VERSION ""

NS_ :

BS_:

BU_: GWM VCU Tester
VAL_TABLE_ New_Value_Table_1 1 "Valid" 0 "Invalid" ;

BO_ 1921 Vcu_Uds_Response: 8 VCU
 SG_ Uds_Resp : 7|64@0+ (1,0) [0|0] ""  Tester

BO_ 1793 Vcu_Uds_Phy_Request: 8 Tester
 SG_ Uds_Phy_Req : 7|64@0+ (1,0) [0|0] ""  VCU

BO_ 1792 Vcu_Uds_Func_Request: 8 Tester
 SG_ Uds_Func_Req : 7|64@0+ (1,0) [0|0] ""  VCU

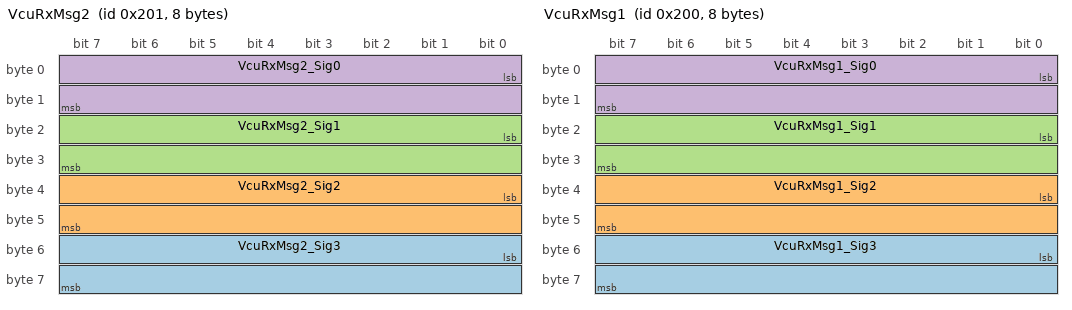
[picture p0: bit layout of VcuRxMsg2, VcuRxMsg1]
BO_ 513 VcuRxMsg2: 8 GWM
 SG_ VcuRxMsg2_Sig3 : 48|16@1- (1,0) [0|0] ""  VCU
 SG_ VcuRxMsg2_Sig2 : 32|16@1- (1,0) [0|0] ""  VCU
 SG_ VcuRxMsg2_Sig1 : 16|16@1- (1,0) [0|0] ""  VCU
 SG_ VcuRxMsg2_Sig0 : 0|16@1- (1,0) [0|0] ""  VCU

BO_ 512 VcuRxMsg1: 8 GWM
 SG_ VcuRxMsg1_Sig3 : 48|16@1- (1,0) [0|0] ""  VCU
 SG_ VcuRxMsg1_Sig2 : 32|16@1- (1,0) [0|0] ""  VCU
 SG_ VcuRxMsg1_Sig1 : 16|16@1- (1,0) [0|0] ""  VCU
 SG_ VcuRxMsg1_Sig0 : 0|16@1- (1,0) [0|0] ""  VCU

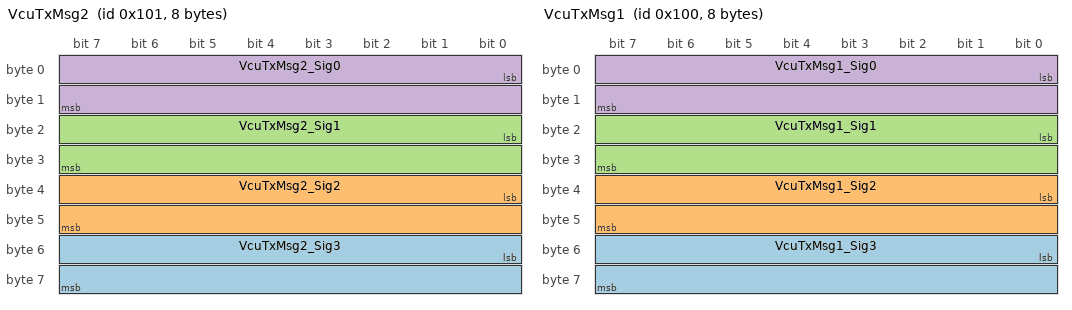
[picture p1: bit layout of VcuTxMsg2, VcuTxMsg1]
BO_ 257 VcuTxMsg2: 8 VCU
 SG_ VcuTxMsg2_Sig3 : 48|16@1- (1,0) [0|0] ""  GWM
 SG_ VcuTxMsg2_Sig2 : 32|16@1- (1,0) [0|0] ""  GWM
 SG_ VcuTxMsg2_Sig1 : 16|16@1- (1,0) [0|0] ""  GWM
 SG_ VcuTxMsg2_Sig0 : 0|16@1- (1,0) [0|0] ""  GWM

BO_ 256 VcuTxMsg1: 8 VCU
 SG_ VcuTxMsg1_Sig3 : 48|16@1- (1,0) [0|0] ""  GWM
 SG_ VcuTxMsg1_Sig2 : 32|16@1- (1,0) [0|0] ""  GWM
 SG_ VcuTxMsg1_Sig1 : 16|16@1- (1,0) [0|0] ""  GWM
 SG_ VcuTxMsg1_Sig0 : 0|16@1- (1,0) [0|0] ""  GWM

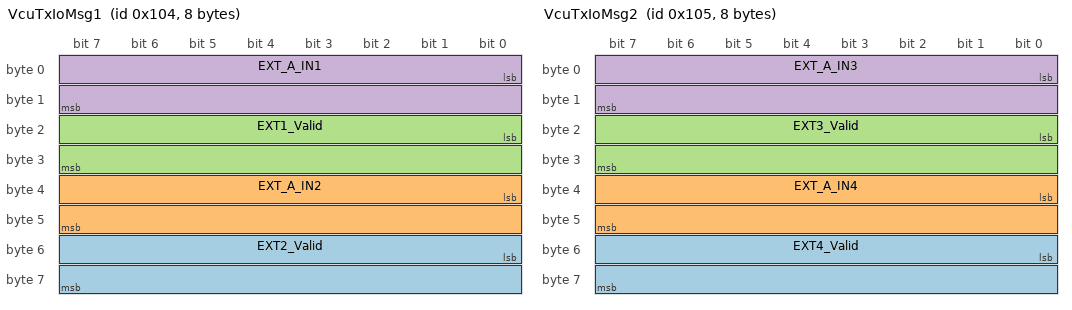
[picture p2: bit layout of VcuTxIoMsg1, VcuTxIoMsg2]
BO_ 260 VcuTxIoMsg1: 8 VCU
 SG_ EXT2_Valid : 48|16@1+ (1,0) [0|1] ""  GWM
 SG_ EXT_A_IN2 : 32|16@1- (1,0) [0|0] "°„C"  GWM
 SG_ EXT1_Valid : 16|16@1+ (1,0) [0|1] ""  GWM
 SG_ EXT_A_IN1 : 0|16@1- (1,0) [-256|255] "°„C"  GWM

BO_ 261 VcuTxIoMsg2: 8 VCU
 SG_ EXT4_Valid : 48|16@1+ (1,0) [0|1] ""  GWM
 SG_ EXT_A_IN4 : 32|16@1- (1,0) [0|0] "°„C"  GWM
 SG_ EXT3_Valid : 16|16@1+ (1,0) [0|1] ""  GWM
 SG_ EXT_A_IN3 : 0|16@1- (1,0) [-256|255] "°„C"  GWM

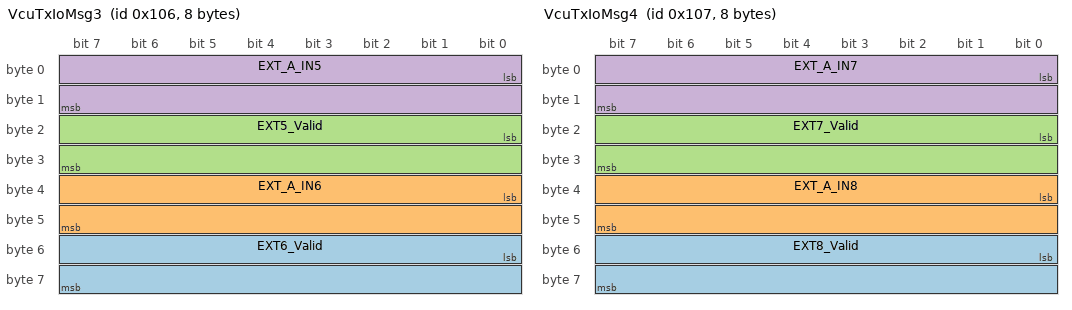
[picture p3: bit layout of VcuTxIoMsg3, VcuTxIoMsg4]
BO_ 262 VcuTxIoMsg3: 8 VCU
 SG_ EXT6_Valid : 48|16@1+ (1,0) [0|1] ""  GWM
 SG_ EXT_A_IN6 : 32|16@1- (1,0) [0|0] "°„C"  GWM
 SG_ EXT5_Valid : 16|16@1+ (1,0) [0|1] ""  GWM
 SG_ EXT_A_IN5 : 0|16@1- (1,0) [-256|255] "°„C"  GWM

BO_ 263 VcuTxIoMsg4: 8 VCU
 SG_ EXT8_Valid : 48|16@1+ (1,0) [0|1] ""  GWM
 SG_ EXT_A_IN8 : 32|16@1- (1,0) [0|0] "°„C"  GWM
 SG_ EXT7_Valid : 16|16@1+ (1,0) [0|1] ""  GWM
 SG_ EXT_A_IN7 : 0|16@1- (1,0) [-256|255] "°„C"  GWM

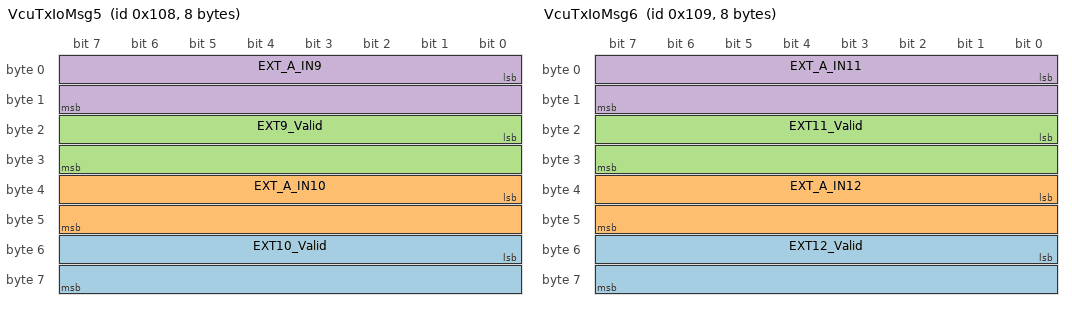
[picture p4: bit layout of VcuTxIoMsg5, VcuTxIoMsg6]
BO_ 264 VcuTxIoMsg5: 8 VCU
 SG_ EXT10_Valid : 48|16@1+ (1,0) [0|1] ""  GWM
 SG_ EXT_A_IN10 : 32|16@1- (1,0) [0|0] "°„C"  GWM
 SG_ EXT9_Valid : 16|16@1+ (1,0) [0|1] ""  GWM
 SG_ EXT_A_IN9 : 0|16@1- (1,0) [-256|255] "°„C"  GWM

BO_ 265 VcuTxIoMsg6: 8 VCU
 SG_ EXT12_Valid : 48|16@1+ (1,0) [0|1] ""  GWM
 SG_ EXT_A_IN12 : 32|16@1- (1,0) [0|0] "°„C"  GWM
 SG_ EXT11_Valid : 16|16@1+ (1,0) [0|1] ""  GWM
 SG_ EXT_A_IN11 : 0|16@1- (1,0) [-256|255] "°„C"  GWM

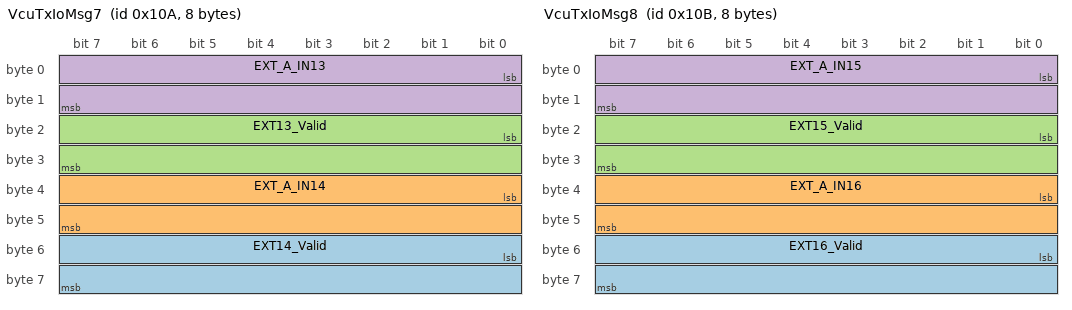
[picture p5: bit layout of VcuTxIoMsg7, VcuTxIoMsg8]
BO_ 266 VcuTxIoMsg7: 8 VCU
 SG_ EXT14_Valid : 48|16@1+ (1,0) [0|1] ""  GWM
 SG_ EXT_A_IN14 : 32|16@1- (1,0) [0|0] "°„C"  GWM
 SG_ EXT13_Valid : 16|16@1+ (1,0) [0|1] ""  GWM
 SG_ EXT_A_IN13 : 0|16@1- (1,0) [-256|255] "°„C"  GWM

BO_ 267 VcuTxIoMsg8: 8 VCU
 SG_ EXT16_Valid : 48|16@1+ (1,0) [0|1] ""  GWM
 SG_ EXT_A_IN16 : 32|16@1- (1,0) [0|0] "°„C"  GWM
 SG_ EXT15_Valid : 16|16@1+ (1,0) [0|1] ""  GWM
 SG_ EXT_A_IN15 : 0|16@1- (1,0) [-256|255] "°„C"  GWM

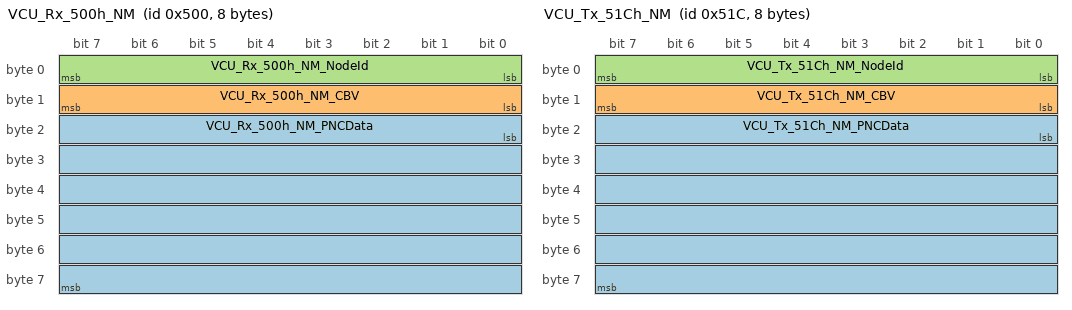
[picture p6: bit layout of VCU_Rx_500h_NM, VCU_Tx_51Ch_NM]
BO_ 1280 VCU_Rx_500h_NM: 8 GWM
 SG_ VCU_Rx_500h_NM_PNCData : 16|48@1+ (1,0) [0|0] ""  VCU
 SG_ VCU_Rx_500h_NM_CBV : 8|8@1+ (1,0) [0|0] ""  VCU
 SG_ VCU_Rx_500h_NM_NodeId : 0|8@1+ (1,0) [0|0] ""  VCU

BO_ 1308 VCU_Tx_51Ch_NM: 8 VCU
 SG_ VCU_Tx_51Ch_NM_PNCData : 16|48@1+ (1,0) [0|0] ""  GWM
 SG_ VCU_Tx_51Ch_NM_CBV : 8|8@1+ (1,0) [0|0] ""  GWM
 SG_ VCU_Tx_51Ch_NM_NodeId : 0|8@1+ (1,0) [0|0] ""  GWM

BO_ 1543 XCP_Response: 8 VCU
 SG_ XCP_Response_Signal : 0|64@1+ (1,0) [0|1.844674407371E+019] ""  Tester

BO_ 1542 XCP_Request: 8 Tester
 SG_ XCP_Request_Signal : 0|64@1+ (1,0) [0|1.844674407371E+019] ""  VCU

BA_DEF_ BO_  "VFrameFormat" ENUM  "StandardCAN","ExtendedCAN","reserved","reserved","reserved","reserved","reserved","reserved","reserved","reserved","reserved","reserved","reserved","reserved","StandardCAN_FD","ExtendedCAN_FD";
BA_DEF_ BO_  "GenMsgCycleTime" INT 0 0;
BA_DEF_ BO_  "GenMsgSendType" ENUM  "Cyclic","NotUsed","NotUsed","NotUsed","NotUsed","NotUsed","NotUsed","IfActive","NoMsgSendType","NotUsed";
BA_DEF_ SG_  "GenSigSendType" ENUM  "Cyclic","OnWrite","OnWriteWithRepetition","OnChange","OnChangeWithRepetition","IfActive","IfActiveWithRepetition","NoSigSendType","NotUsed","NotUsed","NotUsed","NotUsed","NotUsed";
BA_DEF_  "Baudrate" INT 0 1000000;
BA_DEF_  "BusType" STRING ;
BA_DEF_  "NmType" STRING ;
BA_DEF_  "Manufacturer" STRING ;
BA_DEF_ BU_  "NodeLayerModules" STRING ;
BA_DEF_ BO_  "NmMessage" ENUM  "no","yes";
BA_DEF_  "NmAsrWaitBusSleepTime" INT 0 65535;
BA_DEF_  "NmAsrTimeoutTime" INT 1 65535;
BA_DEF_  "NmAsrRepeatMessageTime" INT 0 65535;
BA_DEF_ BU_  "NmAsrNodeIdentifier" HEX 0 255;
BA_DEF_ BU_  "NmAsrNode" ENUM  "no","yes";
BA_DEF_  "NmAsrMessageCount" INT 1 256;
BA_DEF_ BO_  "NmAsrMessage" ENUM  "no","yes";
BA_DEF_ BU_  "NmAsrCanMsgReducedTime" INT 1 65535;
BA_DEF_  "NmAsrCanMsgCycleTime" INT 1 65535;
BA_DEF_  "NmAsrBaseAddress" HEX 0 2047;
BA_DEF_ BU_  "ILUsed" ENUM  "no","yes";
BA_DEF_ BO_  "GenMsgILSupport" ENUM  "no","yes";
BA_DEF_ BO_  "DiagUudtResponse" ENUM  "false","true";
BA_DEF_ BO_  "DiagUudResponse" ENUM  "False","True";
BA_DEF_ BO_  "DiagState" ENUM  "no","yes";
BA_DEF_ BO_  "DiagResponse" ENUM  "no","yes";
BA_DEF_ BO_  "DiagRequest" ENUM  "no","yes";
BA_DEF_  "DBName" STRING ;
BA_DEF_DEF_  "VFrameFormat" "ExtendedCAN_FD";
BA_DEF_DEF_  "GenMsgCycleTime" 0;
BA_DEF_DEF_  "GenMsgSendType" "Cyclic";
BA_DEF_DEF_  "GenSigSendType" "Cyclic";
BA_DEF_DEF_  "Baudrate" 500000;
BA_DEF_DEF_  "BusType" "";
BA_DEF_DEF_  "NmType" "";
BA_DEF_DEF_  "Manufacturer" "Vector";
BA_DEF_DEF_  "NodeLayerModules" " ";
BA_DEF_DEF_  "NmMessage" "no";
BA_DEF_DEF_  "NmAsrWaitBusSleepTime" 2000;
BA_DEF_DEF_  "NmAsrTimeoutTime" 2000;
BA_DEF_DEF_  "NmAsrRepeatMessageTime" 1500;
BA_DEF_DEF_  "NmAsrNodeIdentifier" 28;
BA_DEF_DEF_  "NmAsrNode" "yes";
BA_DEF_DEF_  "NmAsrMessageCount" 128;
BA_DEF_DEF_  "NmAsrMessage" "no";
BA_DEF_DEF_  "NmAsrCanMsgReducedTime" 320;
BA_DEF_DEF_  "NmAsrCanMsgCycleTime" 500;
BA_DEF_DEF_  "NmAsrBaseAddress" 1024;
BA_DEF_DEF_  "ILUsed" "yes";
BA_DEF_DEF_  "GenMsgILSupport" "yes";
BA_DEF_DEF_  "DiagUudtResponse" "false";
BA_DEF_DEF_  "DiagUudResponse" "False";
BA_DEF_DEF_  "DiagState" "no";
BA_DEF_DEF_  "DiagResponse" "no";
BA_DEF_DEF_  "DiagRequest" "no";
BA_DEF_DEF_  "DBName" "";
BA_ "BusType" "CAN";
BA_ "NmType" "NmAsr";
BA_ "DBName" "TC37X_VCU_CAN00";
BA_ "VFrameFormat" BO_ 1921 0;
BA_ "GenMsgSendType" BO_ 1921 8;
BA_ "GenMsgILSupport" BO_ 1921 0;
BA_ "DiagUudResponse" BO_ 1921 1;
BA_ "DiagResponse" BO_ 1921 1;
BA_ "VFrameFormat" BO_ 1793 0;
BA_ "GenMsgSendType" BO_ 1793 8;
BA_ "GenMsgILSupport" BO_ 1793 0;
BA_ "DiagUudResponse" BO_ 1793 1;
BA_ "DiagRequest" BO_ 1793 1;
BA_ "VFrameFormat" BO_ 1792 0;
BA_ "GenMsgSendType" BO_ 1792 8;
BA_ "GenMsgILSupport" BO_ 1792 0;
BA_ "DiagUudtResponse" BO_ 1792 1;
BA_ "DiagState" BO_ 1792 1;
BA_ "VFrameFormat" BO_ 513 0;
BA_ "GenMsgCycleTime" BO_ 513 500;
BA_ "VFrameFormat" BO_ 512 0;
BA_ "GenMsgCycleTime" BO_ 512 500;
BA_ "VFrameFormat" BO_ 257 0;
BA_ "GenMsgCycleTime" BO_ 257 500;
BA_ "VFrameFormat" BO_ 256 0;
BA_ "GenMsgCycleTime" BO_ 256 500;
BA_ "VFrameFormat" BO_ 260 0;
BA_ "GenMsgCycleTime" BO_ 260 500;
BA_ "VFrameFormat" BO_ 261 0;
BA_ "GenMsgCycleTime" BO_ 261 500;
BA_ "VFrameFormat" BO_ 262 0;
BA_ "GenMsgCycleTime" BO_ 262 500;
BA_ "VFrameFormat" BO_ 263 0;
BA_ "GenMsgCycleTime" BO_ 263 500;
BA_ "VFrameFormat" BO_ 264 0;
BA_ "GenMsgCycleTime" BO_ 264 500;
BA_ "VFrameFormat" BO_ 265 0;
BA_ "GenMsgCycleTime" BO_ 265 500;
BA_ "VFrameFormat" BO_ 266 0;
BA_ "GenMsgCycleTime" BO_ 266 500;
BA_ "VFrameFormat" BO_ 267 0;
BA_ "GenMsgCycleTime" BO_ 267 500;
BA_ "VFrameFormat" BO_ 1280 0;
BA_ "GenMsgCycleTime" BO_ 1280 500;
BA_ "NmAsrMessage" BO_ 1280 1;
BA_ "NmMessage" BO_ 1280 1;
BA_ "VFrameFormat" BO_ 1308 0;
BA_ "GenMsgCycleTime" BO_ 1308 500;
BA_ "NmAsrMessage" BO_ 1308 1;
BA_ "NmMessage" BO_ 1308 1;
BA_ "VFrameFormat" BO_ 1543 0;
BA_ "GenMsgILSupport" BO_ 1543 0;
BA_ "GenMsgSendType" BO_ 1543 8;
BA_ "VFrameFormat" BO_ 1542 0;
BA_ "GenMsgILSupport" BO_ 1542 0;
BA_ "GenMsgSendType" BO_ 1542 8;
